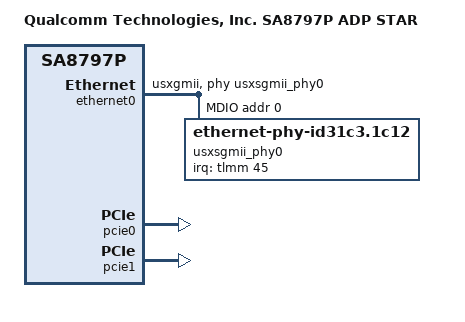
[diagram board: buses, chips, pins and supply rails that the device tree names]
// SPDX-License-Identifier: BSD-3-Clause
/*
 * Copyright (c) 2024-2025 Qualcomm Innovation Center, Inc. All rights reserved.
 */

/dts-v1/;

#include "sa8797p.dtsi"
#include "sa8797p-adp-common.dtsi"

/ {
	model = "Qualcomm Technologies, Inc. SA8797P ADP STAR";
	compatible = "qcom,sa8797p-adp-star", "qcom,sa8797p-adp", "qcom,sa8797p";
	qcom,board-id = <0x010025 0>;

	aliases {
		serial0 = &uart15;
	};
};

&ethernet0 {
	phy-mode = "usxgmii";
	phy-handle = <&usxsgmii_phy0>;

	mdio {
		compatible = "snps,dwmac-mdio";
		#address-cells = <1>;
		#size-cells = <0>;

		usxsgmii_phy0: phy@0 {
			compatible = "ethernet-phy-id31c3.1c12";
			reg = <0x0>;
			device_type = "ethernet-phy";
			interrupts-extended = <&tlmm 45 IRQ_TYPE_EDGE_FALLING>;
			resets = <&scmi7_rst 0>;
			reset-names = "phy";
			reset-assert-us = <100000>;
			reset-deassert-us = <100000>;
		};
	};
};

&xpcs1 {
	status = "disabled";
};

&ethernet1 {
	status = "disabled";

	phy-mode = "usxgmii";
	phy-handle = <&usxsgmii_phy1>;

	mdio {
		compatible = "snps,dwmac-mdio";
		#address-cells = <1>;
		#size-cells = <0>;

		usxsgmii_phy1: phy@8 {
			compatible = "ethernet-phy-id31c3.1c12";
			reg = <0x8>;
			device_type = "ethernet-phy";
			interrupts-extended = <&tlmm 46 IRQ_TYPE_EDGE_FALLING>;
			resets = <&scmi8_rst 0>;
			reset-names = "phy";
			reset-assert-us = <100000>;
			reset-deassert-us = <100000>;
		};
	};
};

&pcie0 {
	power-domains = <&scmi5_pd 0>;
	power-domain-names = "power";
	status = "okay";
};

&pcie1 {
	power-domains = <&scmi6_pd 0>;
	power-domain-names = "power";
	status = "okay";
};
